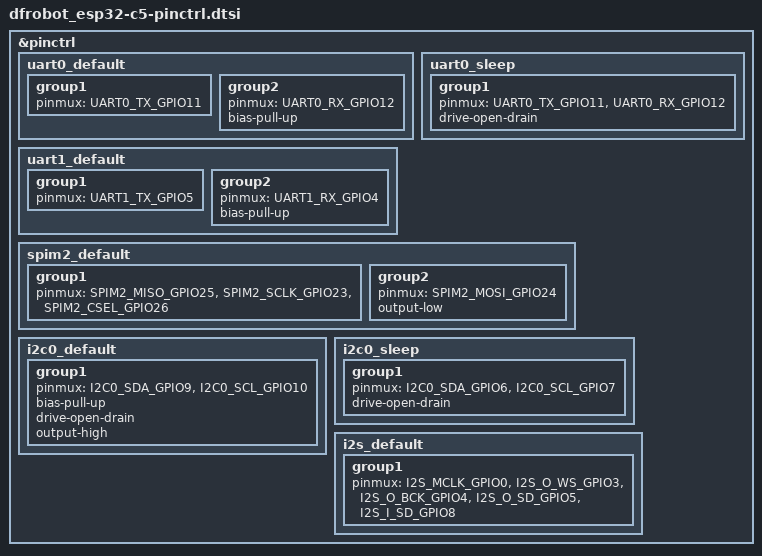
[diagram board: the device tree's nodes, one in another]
#include <zephyr/dt-bindings/pinctrl/esp32-pinctrl.h>

&pinctrl {
	uart0_default: uart0_default {
		group1 {
			pinmux = <UART0_TX_GPIO11>;
		};

		group2 {
			pinmux = <UART0_RX_GPIO12>;
			bias-pull-up;
		};
	};

	uart0_sleep: uart0_sleep {
		group1 {
			pinmux = <UART0_TX_GPIO11>,
				 <UART0_RX_GPIO12>;
			drive-open-drain;
		};
	};

	uart1_default: uart1_default {
		group1 {
			pinmux = <UART1_TX_GPIO5>;
		};

		group2 {
			pinmux = <UART1_RX_GPIO4>;
			bias-pull-up;
		};
	};

	spim2_default: spim2_default {
		group1 {
			pinmux = <SPIM2_MISO_GPIO25>,
				 <SPIM2_SCLK_GPIO23>,
				 <SPIM2_CSEL_GPIO26>;
		};

		group2 {
			pinmux = <SPIM2_MOSI_GPIO24>;
			output-low;
		};
	};

	i2c0_default: i2c0_default {
		group1 {
			pinmux = <I2C0_SDA_GPIO9>,
				 <I2C0_SCL_GPIO10>;
			bias-pull-up;
			drive-open-drain;
			output-high;
		};
	};

	i2c0_sleep: i2c0_sleep {
		group1 {
			pinmux = <I2C0_SDA_GPIO6>,
				 <I2C0_SCL_GPIO7>;
			drive-open-drain;
		};
	};

	i2s_default: i2s_default {
		group1 {
			pinmux = <I2S_MCLK_GPIO0>,
				 <I2S_O_WS_GPIO3>,
				 <I2S_O_BCK_GPIO4>,
				 <I2S_O_SD_GPIO5>,
				 <I2S_I_SD_GPIO8>;
		};
	};
};
